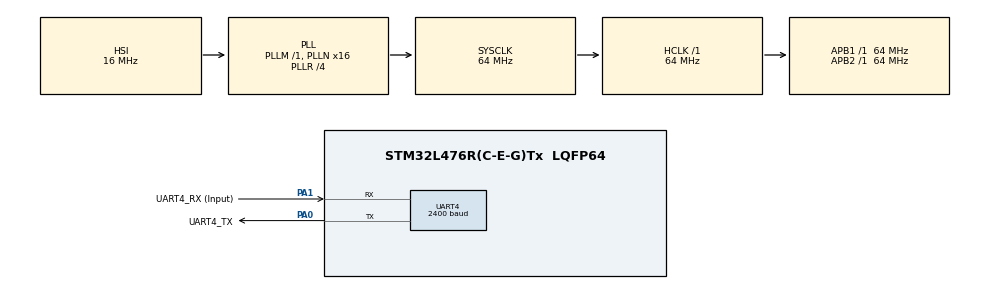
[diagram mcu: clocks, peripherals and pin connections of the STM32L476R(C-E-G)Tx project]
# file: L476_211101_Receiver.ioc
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Mcu.Family=STM32L4
RCC.MSI_VALUE=4000000
RCC.PLLSourceVirtual=RCC_PLLSOURCE_HSI
PA14\ (JTCK-SWCLK).Mode=Serial_Wire
RCC.CortexFreq_Value=64000000
PA0.GPIO_Label=UART4_TX
RCC.SYSCLKSource=RCC_SYSCLKSOURCE_PLLCLK
ProjectManager.StackSize=0x400
PA14\ (JTCK-SWCLK).Signal=SYS_JTCK-SWCLK
ProjectManager.TargetToolchain=STM32CubeIDE
UART4.BaudRate=2400
UART4.Mode=MODE_TX_RX
RCC.HCLKFreq_Value=64000000
RCC.APB2TimFreq_Value=64000000
UART4.Parity=PARITY_EVEN
RCC.USBFreq_Value=64000000
RCC.LSE_VALUE=32768
PA1.Signal=UART4_RX
RCC.AHBFreq_Value=64000000
RCC.HSE_VALUE=48000000
board=custom
RCC.VCOOutputFreq_Value=256000000
RCC.APB2Freq_Value=64000000
PA1.Mode=Asynchronous
RCC.ADCFreq_Value=64000000
PA1.GPIO_Label=UART4_RX (Input)
PA0.Mode=Asynchronous
Mcu.Name=STM32L476R(C-E-G)Tx
PA0.Signal=UART4_TX
PA13\ (JTMS-SWDIO).Mode=Serial_Wire
RCC.SYSCLKFreq_VALUE=64000000
Mcu.Package=LQFP64
ProjectManager.HeapSize=0x200
RCC.HSI_VALUE=16000000
NVIC.PriorityGroup=NVIC_PRIORITYGROUP_4
RCC.PLLR=RCC_PLLR_DIV4
RCC.PLLN=16
RCC.APB1TimFreq_Value=64000000
PA13\ (JTMS-SWDIO).Signal=SYS_JTMS-SWDIO
RCC.APB1Freq_Value=64000000
NVIC.UART4_IRQn=true\:1\:0\:true\:false\:true\:true\:true

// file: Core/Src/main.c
/* USER CODE BEGIN Header */
/**
  ******************************************************************************
  * @file           : main.c
  * @brief          : Main program body
  ******************************************************************************
  * @attention
  *
  * <h2><center>&copy; Copyright (c) 2021 STMicroelectronics.
  * All rights reserved.</center></h2>
  *
  * This software component is licensed by ST under BSD 3-Clause license,
  * the "License"; You may not use this file except in compliance with the
  * License. You may obtain a copy of the License at:
  *                        opensource.org/licenses/BSD-3-Clause
  *
  ******************************************************************************
  */
/* USER CODE END Header */
#include "main.h"

/* USER CODE BEGIN Includes */
#include "receiver.h"
#include "transmitter.h"

/* USER CODE END Includes */

UART_HandleTypeDef huart4;

void SystemClock_Config(void);
static void MX_GPIO_Init(void);
static void MX_UART4_Init(void);

int main(void)
{

  /* MCU Configuration--------------------------------------------------------*/

  /* Reset of all peripherals, Initializes the Flash interface and the Systick. */
  HAL_Init();

  /* Configure the system clock */
  SystemClock_Config();

  /* Initialize all configured peripherals */
  MX_GPIO_Init();
  MX_UART4_Init();
  /* USER CODE BEGIN 2 */
  HAL_UART_Receive_IT(&huart4, (uint8_t *)buffRx, sizeof(buffRx));

  /* USER CODE END 2 */

  /* Infinite loop */
  /* USER CODE BEGIN WHILE */
  while (1)
  {
	// Bugfix: uC ist nach etwa einer Minute von den Interrupt-Callbacks (grundlos?) in die while-Schleife gesprungen
	HAL_UART_Receive_IT(&huart4, (uint8_t *)buffRx, sizeof(buffRx));
    /* USER CODE END WHILE */

  }
}

void SystemClock_Config(void)
{
  RCC_OscInitTypeDef RCC_OscInitStruct = {0};
  RCC_ClkInitTypeDef RCC_ClkInitStruct = {0};
  RCC_PeriphCLKInitTypeDef PeriphClkInit = {0};

  /** Initializes the RCC Oscillators according to the specified parameters
  * in the RCC_OscInitTypeDef structure.
  */
  RCC_OscInitStruct.OscillatorType = RCC_OSCILLATORTYPE_HSI;
  RCC_OscInitStruct.HSIState = RCC_HSI_ON;
  RCC_OscInitStruct.HSICalibrationValue = RCC_HSICALIBRATION_DEFAULT;
  RCC_OscInitStruct.PLL.PLLState = RCC_PLL_ON;
  RCC_OscInitStruct.PLL.PLLSource = RCC_PLLSOURCE_HSI;
  RCC_OscInitStruct.PLL.PLLM = 1;
  RCC_OscInitStruct.PLL.PLLN = 16;
  RCC_OscInitStruct.PLL.PLLP = RCC_PLLP_DIV7;
  RCC_OscInitStruct.PLL.PLLQ = RCC_PLLQ_DIV2;
  RCC_OscInitStruct.PLL.PLLR = RCC_PLLR_DIV4;
  if (HAL_RCC_OscConfig(&RCC_OscInitStruct) != HAL_OK)
  {
    Error_Handler();
  }
  /** Initializes the CPU, AHB and APB buses clocks
  */
  RCC_ClkInitStruct.ClockType = RCC_CLOCKTYPE_HCLK|RCC_CLOCKTYPE_SYSCLK
                              |RCC_CLOCKTYPE_PCLK1|RCC_CLOCKTYPE_PCLK2;
  RCC_ClkInitStruct.SYSCLKSource = RCC_SYSCLKSOURCE_PLLCLK;
  RCC_ClkInitStruct.AHBCLKDivider = RCC_SYSCLK_DIV1;
  RCC_ClkInitStruct.APB1CLKDivider = RCC_HCLK_DIV1;
  RCC_ClkInitStruct.APB2CLKDivider = RCC_HCLK_DIV1;

  if (HAL_RCC_ClockConfig(&RCC_ClkInitStruct, FLASH_LATENCY_3) != HAL_OK)
  {
    Error_Handler();
  }
  PeriphClkInit.PeriphClockSelection = RCC_PERIPHCLK_UART4;
  PeriphClkInit.Uart4ClockSelection = RCC_UART4CLKSOURCE_PCLK1;
  if (HAL_RCCEx_PeriphCLKConfig(&PeriphClkInit) != HAL_OK)
  {
    Error_Handler();
  }
  /** Configure the main internal regulator output voltage
  */
  if (HAL_PWREx_ControlVoltageScaling(PWR_REGULATOR_VOLTAGE_SCALE1) != HAL_OK)
  {
    Error_Handler();
  }
}

static void MX_UART4_Init(void)
{

  huart4.Instance = UART4;
  huart4.Init.BaudRate = 2400;
  huart4.Init.WordLength = UART_WORDLENGTH_8B;
  huart4.Init.StopBits = UART_STOPBITS_1;
  huart4.Init.Parity = UART_PARITY_EVEN;
  huart4.Init.Mode = UART_MODE_TX_RX;
  huart4.Init.HwFlowCtl = UART_HWCONTROL_NONE;
  huart4.Init.OverSampling = UART_OVERSAMPLING_16;
  huart4.Init.OneBitSampling = UART_ONE_BIT_SAMPLE_DISABLE;
  huart4.AdvancedInit.AdvFeatureInit = UART_ADVFEATURE_NO_INIT;
  if (HAL_UART_Init(&huart4) != HAL_OK)
  {
    Error_Handler();
  }

}

static void MX_GPIO_Init(void)
{

  /* GPIO Ports Clock Enable */
  __HAL_RCC_GPIOA_CLK_ENABLE();

}

void Error_Handler(void)
{
  __disable_irq();
  while (1)
  {
  }
}

/************************ (C) COPYRIGHT STMicroelectronics *****END OF FILE****/
